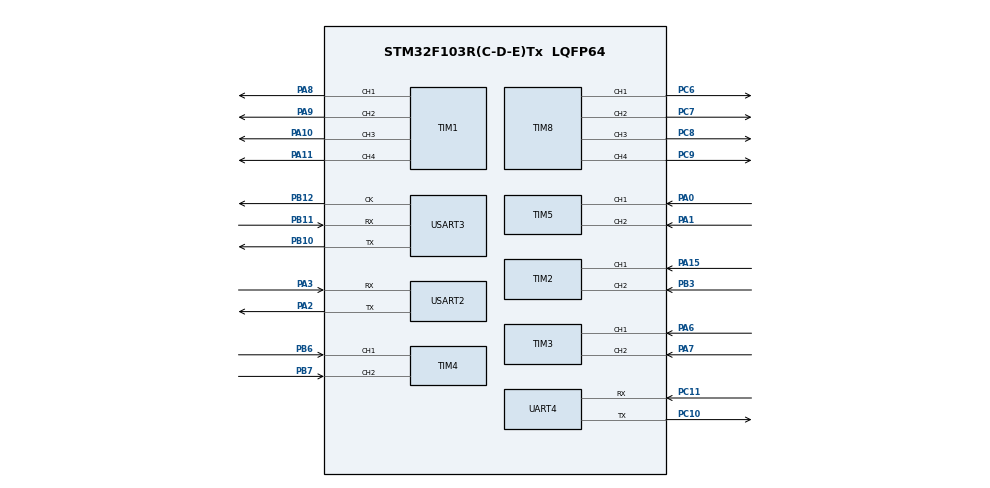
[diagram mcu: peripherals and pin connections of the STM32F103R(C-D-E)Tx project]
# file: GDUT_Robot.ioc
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Dma.Request0=USART3_RX
Dma.Request1=USART3_TX
Dma.USART3_RX.0.Direction=DMA_PERIPH_TO_MEMORY
Dma.USART3_RX.0.Instance=DMA1_Channel3
Dma.USART3_RX.0.MemDataAlignment=DMA_MDATAALIGN_BYTE
Dma.USART3_RX.0.MemInc=DMA_MINC_ENABLE
Dma.USART3_RX.0.Mode=DMA_NORMAL
Dma.USART3_RX.0.PeriphDataAlignment=DMA_PDATAALIGN_BYTE
Dma.USART3_RX.0.PeriphInc=DMA_PINC_DISABLE
Dma.USART3_RX.0.Priority=DMA_PRIORITY_MEDIUM
Dma.USART3_TX.1.Direction=DMA_MEMORY_TO_PERIPH
Dma.USART3_TX.1.Instance=DMA1_Channel2
Dma.USART3_TX.1.MemDataAlignment=DMA_MDATAALIGN_BYTE
Dma.USART3_TX.1.MemInc=DMA_MINC_ENABLE
Dma.USART3_TX.1.Mode=DMA_NORMAL
Dma.USART3_TX.1.PeriphDataAlignment=DMA_PDATAALIGN_BYTE
Dma.USART3_TX.1.PeriphInc=DMA_PINC_DISABLE
Dma.USART3_TX.1.Priority=DMA_PRIORITY_MEDIUM
Mcu.Family=STM32F1
Mcu.Name=STM32F103R(C-D-E)Tx
Mcu.Package=LQFP64
NVIC.DMA1_Channel2_IRQn=true\:0\:0\:false\:false\:true\:false\:true
NVIC.DMA1_Channel3_IRQn=true\:0\:0\:false\:false\:true\:false\:true
NVIC.PriorityGroup=NVIC_PRIORITYGROUP_4
NVIC.TIM6_IRQn=true\:0\:0\:false\:false\:true\:true\:true
NVIC.UART4_IRQn=true\:0\:0\:false\:false\:true\:true\:true
NVIC.USART3_IRQn=true\:0\:0\:false\:false\:true\:true\:true
PA0-WKUP.Signal=S_TIM5_CH1
PA1.Signal=S_TIM5_CH2
PA10.Signal=S_TIM1_CH3
PA11.Signal=S_TIM1_CH4
PA13.Mode=Serial_Wire
PA13.Signal=SYS_JTMS-SWDIO
PA14.Mode=Serial_Wire
PA14.Signal=SYS_JTCK-SWCLK
PA15.Signal=S_TIM2_CH1_ETR
PA2.Mode=Asynchronous
PA2.Signal=USART2_TX
PA3.Mode=Asynchronous
PA3.Signal=USART2_RX
PA6.Signal=S_TIM3_CH1
PA7.Signal=S_TIM3_CH2
PA8.Signal=S_TIM1_CH1
PA9.Signal=S_TIM1_CH2
PB10.Mode=Synchronous
PB10.Signal=USART3_TX
PB11.Mode=Synchronous
PB11.Signal=USART3_RX
PB12.Mode=Synchronous
PB12.Signal=USART3_CK
PB3.Signal=S_TIM2_CH2
PB6.Signal=S_TIM4_CH1
PB7.Signal=S_TIM4_CH2
PC10.Mode=Asynchronous
PC10.Signal=UART4_TX
PC11.Mode=Asynchronous
PC11.Signal=UART4_RX
PC6.Signal=S_TIM8_CH1
PC7.Signal=S_TIM8_CH2
PC8.Signal=S_TIM8_CH3
PC9.Signal=S_TIM8_CH4
PD0-OSC_IN.Mode=HSE-External-Oscillator
PD0-OSC_IN.Signal=RCC_OSC_IN
PD1-OSC_OUT.Mode=HSE-External-Oscillator
PD1-OSC_OUT.Signal=RCC_OSC_OUT
ProjectManager.HeapSize=0x200
ProjectManager.StackSize=0x400
ProjectManager.TargetToolchain=SW4STM32
RCC.APB1Freq_Value=8000000
RCC.APB2Freq_Value=8000000
SH.S_TIM1_CH1.0=TIM1_CH1,PWM Generation1 CH1
SH.S_TIM1_CH2.0=TIM1_CH2,PWM Generation2 CH2
SH.S_TIM1_CH3.0=TIM1_CH3,Output Compare3 CH3
SH.S_TIM1_CH4.0=TIM1_CH4,Output Compare4 CH4
SH.S_TIM2_CH1_ETR.0=TIM2_CH1,Encoder_Interface
SH.S_TIM2_CH2.0=TIM2_CH2,Encoder_Interface
SH.S_TIM3_CH1.0=TIM3_CH1,Encoder_Interface
SH.S_TIM3_CH2.0=TIM3_CH2,Encoder_Interface
SH.S_TIM4_CH1.0=TIM4_CH1,Encoder_Interface
SH.S_TIM4_CH2.0=TIM4_CH2,Encoder_Interface
SH.S_TIM5_CH1.0=TIM5_CH1,Encoder_Interface
SH.S_TIM5_CH2.0=TIM5_CH2,Encoder_Interface
SH.S_TIM8_CH1.0=TIM8_CH1,Output Compare1 CH1
SH.S_TIM8_CH2.0=TIM8_CH2,Output Compare2 CH2
SH.S_TIM8_CH3.0=TIM8_CH3,Output Compare3 CH3
SH.S_TIM8_CH4.0=TIM8_CH4,Output Compare4 CH4
TIM1.Channel-Output\ Compare3\ CH3=TIM_CHANNEL_3
TIM1.Channel-Output\ Compare4\ CH4=TIM_CHANNEL_4
TIM1.Channel-PWM\ Generation1\ CH1=TIM_CHANNEL_1
TIM1.Channel-PWM\ Generation2\ CH2=TIM_CHANNEL_2
TIM6.Period=7200-1
TIM6.Prescaler=10-1
TIM8.Channel-Output\ Compare1\ CH1=TIM_CHANNEL_1
TIM8.Channel-Output\ Compare2\ CH2=TIM_CHANNEL_2
TIM8.Channel-Output\ Compare3\ CH3=TIM_CHANNEL_3
TIM8.Channel-Output\ Compare4\ CH4=TIM_CHANNEL_4
UART4.VirtualMode=Asynchronous
USART2.VirtualMode=VM_ASYNC
USART3.VirtualMode=VM_SYNC
VP_TIM1_VS_ClockSourceINT.Mode=Internal
VP_TIM6_VS_ClockSourceINT.Mode=Enable_Timer
VP_TIM8_VS_ClockSourceINT.Mode=Internal
board=custom

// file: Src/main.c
/* USER CODE BEGIN Header */
/**
 ******************************************************************************
 * @file           : main.c
 * @brief          : Main program body
 ******************************************************************************
 * @attention
 *
 * <h2><center>&copy; Copyright (c) 2021 STMicroelectronics.
 * All rights reserved.</center></h2>
 *
 * This software component is licensed by ST under BSD 3-Clause license,
 * the "License"; You may not use this file except in compliance with the
 * License. You may obtain a copy of the License at:
 *                        opensource.org/licenses/BSD-3-Clause
 *
 ******************************************************************************
 */
/* USER CODE END Header */
#include "main.h"

/* USER CODE BEGIN Includes */
#include "PID_struct.h"
#include "motor.h"
#include "tim_it.h"
#include "retarget.h"
/* USER CODE END Includes */

TIM_HandleTypeDef htim1;
TIM_HandleTypeDef htim2;
TIM_HandleTypeDef htim3;
TIM_HandleTypeDef htim4;
TIM_HandleTypeDef htim5;
TIM_HandleTypeDef htim6;
TIM_HandleTypeDef htim8;

UART_HandleTypeDef huart4;
UART_HandleTypeDef huart2;
USART_HandleTypeDef husart3;
DMA_HandleTypeDef hdma_usart3_rx;
DMA_HandleTypeDef hdma_usart3_tx;

void SystemClock_Config(void);
static void MX_GPIO_Init(void);
static void MX_DMA_Init(void);
static void MX_TIM1_Init(void);
static void MX_TIM3_Init(void);
static void MX_TIM6_Init(void);
static void MX_UART4_Init(void);
static void MX_USART3_Init(void);
static void MX_TIM2_Init(void);
static void MX_USART2_UART_Init(void);
static void MX_TIM5_Init(void);
static void MX_TIM8_Init(void);
static void MX_TIM4_Init(void);

int main(void)
{

  /* MCU Configuration--------------------------------------------------------*/

  /* Reset of all peripherals, Initializes the Flash interface and the Systick. */
  HAL_Init();

  /* Configure the system clock */
  SystemClock_Config();

  /* Initialize all configured peripherals */
  MX_GPIO_Init();
  MX_DMA_Init();
  MX_TIM1_Init();
  MX_TIM3_Init();
  MX_TIM6_Init();
  MX_UART4_Init();
  MX_USART3_Init();
  MX_TIM2_Init();
  MX_USART2_UART_Init();
  MX_TIM5_Init();
  MX_TIM8_Init();
  MX_TIM4_Init();
  /* USER CODE BEGIN 2 */
    RetargetInit(&huart2);
    step = 0;
    PID_Init(); //
    HAL_TIM_Base_Start_IT(&htim6);
    printf("ball ball you  1\n");
  /* USER CODE END 2 */

  /* Infinite loop */
    while (1){

    }
}

void SystemClock_Config(void)
{
  RCC_OscInitTypeDef RCC_OscInitStruct = {0};
  RCC_ClkInitTypeDef RCC_ClkInitStruct = {0};

  /** Initializes the RCC Oscillators according to the specified parameters
  * in the RCC_OscInitTypeDef structure.
  */
  RCC_OscInitStruct.OscillatorType = RCC_OSCILLATORTYPE_HSI;
  RCC_OscInitStruct.HSIState = RCC_HSI_ON;
  RCC_OscInitStruct.HSICalibrationValue = RCC_HSICALIBRATION_DEFAULT;
  RCC_OscInitStruct.PLL.PLLState = RCC_PLL_NONE;
  if (HAL_RCC_OscConfig(&RCC_OscInitStruct) != HAL_OK)
  {
    Error_Handler();
  }
  /** Initializes the CPU, AHB and APB buses clocks
  */
  RCC_ClkInitStruct.ClockType = RCC_CLOCKTYPE_HCLK|RCC_CLOCKTYPE_SYSCLK
                              |RCC_CLOCKTYPE_PCLK1|RCC_CLOCKTYPE_PCLK2;
  RCC_ClkInitStruct.SYSCLKSource = RCC_SYSCLKSOURCE_HSI;
  RCC_ClkInitStruct.AHBCLKDivider = RCC_SYSCLK_DIV1;
  RCC_ClkInitStruct.APB1CLKDivider = RCC_HCLK_DIV1;
  RCC_ClkInitStruct.APB2CLKDivider = RCC_HCLK_DIV1;

  if (HAL_RCC_ClockConfig(&RCC_ClkInitStruct, FLASH_LATENCY_0) != HAL_OK)
  {
    Error_Handler();
  }
}

static void MX_TIM1_Init(void)
{

  TIM_ClockConfigTypeDef sClockSourceConfig = {0};
  TIM_MasterConfigTypeDef sMasterConfig = {0};
  TIM_OC_InitTypeDef sConfigOC = {0};
  TIM_BreakDeadTimeConfigTypeDef sBreakDeadTimeConfig = {0};

  htim1.Instance = TIM1;
  htim1.Init.Prescaler = 0;
  htim1.Init.CounterMode = TIM_COUNTERMODE_UP;
  htim1.Init.Period = 65535;
  htim1.Init.ClockDivision = TIM_CLOCKDIVISION_DIV1;
  htim1.Init.RepetitionCounter = 0;
  htim1.Init.AutoReloadPreload = TIM_AUTORELOAD_PRELOAD_DISABLE;
  if (HAL_TIM_Base_Init(&htim1) != HAL_OK)
  {
    Error_Handler();
  }
  sClockSourceConfig.ClockSource = TIM_CLOCKSOURCE_INTERNAL;
  if (HAL_TIM_ConfigClockSource(&htim1, &sClockSourceConfig) != HAL_OK)
  {
    Error_Handler();
  }
  if (HAL_TIM_PWM_Init(&htim1) != HAL_OK)
  {
    Error_Handler();
  }
  if (HAL_TIM_OC_Init(&htim1) != HAL_OK)
  {
    Error_Handler();
  }
  sMasterConfig.MasterOutputTrigger = TIM_TRGO_RESET;
  sMasterConfig.MasterSlaveMode = TIM_MASTERSLAVEMODE_DISABLE;
  if (HAL_TIMEx_MasterConfigSynchronization(&htim1, &sMasterConfig) != HAL_OK)
  {
    Error_Handler();
  }
  sConfigOC.OCMode = TIM_OCMODE_PWM1;
  sConfigOC.Pulse = 0;
  sConfigOC.OCPolarity = TIM_OCPOLARITY_HIGH;
  sConfigOC.OCNPolarity = TIM_OCNPOLARITY_HIGH;
  sConfigOC.OCFastMode = TIM_OCFAST_DISABLE;
  sConfigOC.OCIdleState = TIM_OCIDLESTATE_RESET;
  sConfigOC.OCNIdleState = TIM_OCNIDLESTATE_RESET;
  if (HAL_TIM_PWM_ConfigChannel(&htim1, &sConfigOC, TIM_CHANNEL_1) != HAL_OK)
  {
    Error_Handler();
  }
  if (HAL_TIM_PWM_ConfigChannel(&htim1, &sConfigOC, TIM_CHANNEL_2) != HAL_OK)
  {
    Error_Handler();
  }
  sConfigOC.OCMode = TIM_OCMODE_TIMING;
  if (HAL_TIM_OC_ConfigChannel(&htim1, &sConfigOC, TIM_CHANNEL_3) != HAL_OK)
  {
    Error_Handler();
  }
  if (HAL_TIM_OC_ConfigChannel(&htim1, &sConfigOC, TIM_CHANNEL_4) != HAL_OK)
  {
    Error_Handler();
  }
  sBreakDeadTimeConfig.OffStateRunMode = TIM_OSSR_DISABLE;
  sBreakDeadTimeConfig.OffStateIDLEMode = TIM_OSSI_DISABLE;
  sBreakDeadTimeConfig.LockLevel = TIM_LOCKLEVEL_OFF;
  sBreakDeadTimeConfig.DeadTime = 0;
  sBreakDeadTimeConfig.BreakState = TIM_BREAK_DISABLE;
  sBreakDeadTimeConfig.BreakPolarity = TIM_BREAKPOLARITY_HIGH;
  sBreakDeadTimeConfig.AutomaticOutput = TIM_AUTOMATICOUTPUT_DISABLE;
  if (HAL_TIMEx_ConfigBreakDeadTime(&htim1, &sBreakDeadTimeConfig) != HAL_OK)
  {
    Error_Handler();
  }
  HAL_TIM_MspPostInit(&htim1);

}

static void MX_TIM2_Init(void)
{

  TIM_Encoder_InitTypeDef sConfig = {0};
  TIM_MasterConfigTypeDef sMasterConfig = {0};

  htim2.Instance = TIM2;
  htim2.Init.Prescaler = 0;
  htim2.Init.CounterMode = TIM_COUNTERMODE_UP;
  htim2.Init.Period = 65535;
  htim2.Init.ClockDivision = TIM_CLOCKDIVISION_DIV1;
  htim2.Init.AutoReloadPreload = TIM_AUTORELOAD_PRELOAD_DISABLE;
  sConfig.EncoderMode = TIM_ENCODERMODE_TI1;
  sConfig.IC1Polarity = TIM_ICPOLARITY_RISING;
  sConfig.IC1Selection = TIM_ICSELECTION_DIRECTTI;
  sConfig.IC1Prescaler = TIM_ICPSC_DIV1;
  sConfig.IC1Filter = 0;
  sConfig.IC2Polarity = TIM_ICPOLARITY_RISING;
  sConfig.IC2Selection = TIM_ICSELECTION_DIRECTTI;
  sConfig.IC2Prescaler = TIM_ICPSC_DIV1;
  sConfig.IC2Filter = 0;
  if (HAL_TIM_Encoder_Init(&htim2, &sConfig) != HAL_OK)
  {
    Error_Handler();
  }
  sMasterConfig.MasterOutputTrigger = TIM_TRGO_RESET;
  sMasterConfig.MasterSlaveMode = TIM_MASTERSLAVEMODE_DISABLE;
  if (HAL_TIMEx_MasterConfigSynchronization(&htim2, &sMasterConfig) != HAL_OK)
  {
    Error_Handler();
  }

}

static void MX_TIM3_Init(void)
{

  TIM_Encoder_InitTypeDef sConfig = {0};
  TIM_MasterConfigTypeDef sMasterConfig = {0};

  htim3.Instance = TIM3;
  htim3.Init.Prescaler = 0;
  htim3.Init.CounterMode = TIM_COUNTERMODE_UP;
  htim3.Init.Period = 65535;
  htim3.Init.ClockDivision = TIM_CLOCKDIVISION_DIV1;
  htim3.Init.AutoReloadPreload = TIM_AUTORELOAD_PRELOAD_DISABLE;
  sConfig.EncoderMode = TIM_ENCODERMODE_TI1;
  sConfig.IC1Polarity = TIM_ICPOLARITY_RISING;
  sConfig.IC1Selection = TIM_ICSELECTION_DIRECTTI;
  sConfig.IC1Prescaler = TIM_ICPSC_DIV1;
  sConfig.IC1Filter = 0;
  sConfig.IC2Polarity = TIM_ICPOLARITY_RISING;
  sConfig.IC2Selection = TIM_ICSELECTION_DIRECTTI;
  sConfig.IC2Prescaler = TIM_ICPSC_DIV1;
  sConfig.IC2Filter = 0;
  if (HAL_TIM_Encoder_Init(&htim3, &sConfig) != HAL_OK)
  {
    Error_Handler();
  }
  sMasterConfig.MasterOutputTrigger = TIM_TRGO_RESET;
  sMasterConfig.MasterSlaveMode = TIM_MASTERSLAVEMODE_DISABLE;
  if (HAL_TIMEx_MasterConfigSynchronization(&htim3, &sMasterConfig) != HAL_OK)
  {
    Error_Handler();
  }

}

static void MX_TIM4_Init(void)
{

  TIM_Encoder_InitTypeDef sConfig = {0};
  TIM_MasterConfigTypeDef sMasterConfig = {0};

  htim4.Instance = TIM4;
  htim4.Init.Prescaler = 0;
  htim4.Init.CounterMode = TIM_COUNTERMODE_UP;
  htim4.Init.Period = 65535;
  htim4.Init.ClockDivision = TIM_CLOCKDIVISION_DIV1;
  htim4.Init.AutoReloadPreload = TIM_AUTORELOAD_PRELOAD_DISABLE;
  sConfig.EncoderMode = TIM_ENCODERMODE_TI1;
  sConfig.IC1Polarity = TIM_ICPOLARITY_RISING;
  sConfig.IC1Selection = TIM_ICSELECTION_DIRECTTI;
  sConfig.IC1Prescaler = TIM_ICPSC_DIV1;
  sConfig.IC1Filter = 0;
  sConfig.IC2Polarity = TIM_ICPOLARITY_RISING;
  sConfig.IC2Selection = TIM_ICSELECTION_DIRECTTI;
  sConfig.IC2Prescaler = TIM_ICPSC_DIV1;
  sConfig.IC2Filter = 0;
  if (HAL_TIM_Encoder_Init(&htim4, &sConfig) != HAL_OK)
  {
    Error_Handler();
  }
  sMasterConfig.MasterOutputTrigger = TIM_TRGO_RESET;
  sMasterConfig.MasterSlaveMode = TIM_MASTERSLAVEMODE_DISABLE;
  if (HAL_TIMEx_MasterConfigSynchronization(&htim4, &sMasterConfig) != HAL_OK)
  {
    Error_Handler();
  }

}

static void MX_TIM5_Init(void)
{

  TIM_Encoder_InitTypeDef sConfig = {0};
  TIM_MasterConfigTypeDef sMasterConfig = {0};

  htim5.Instance = TIM5;
  htim5.Init.Prescaler = 0;
  htim5.Init.CounterMode = TIM_COUNTERMODE_UP;
  htim5.Init.Period = 65535;
  htim5.Init.ClockDivision = TIM_CLOCKDIVISION_DIV1;
  htim5.Init.AutoReloadPreload = TIM_AUTORELOAD_PRELOAD_DISABLE;
  sConfig.EncoderMode = TIM_ENCODERMODE_TI1;
  sConfig.IC1Polarity = TIM_ICPOLARITY_RISING;
  sConfig.IC1Selection = TIM_ICSELECTION_DIRECTTI;
  sConfig.IC1Prescaler = TIM_ICPSC_DIV1;
  sConfig.IC1Filter = 0;
  sConfig.IC2Polarity = TIM_ICPOLARITY_RISING;
  sConfig.IC2Selection = TIM_ICSELECTION_DIRECTTI;
  sConfig.IC2Prescaler = TIM_ICPSC_DIV1;
  sConfig.IC2Filter = 0;
  if (HAL_TIM_Encoder_Init(&htim5, &sConfig) != HAL_OK)
  {
    Error_Handler();
  }
  sMasterConfig.MasterOutputTrigger = TIM_TRGO_RESET;
  sMasterConfig.MasterSlaveMode = TIM_MASTERSLAVEMODE_DISABLE;
  if (HAL_TIMEx_MasterConfigSynchronization(&htim5, &sMasterConfig) != HAL_OK)
  {
    Error_Handler();
  }

}

static void MX_TIM6_Init(void)
{

  TIM_MasterConfigTypeDef sMasterConfig = {0};

  htim6.Instance = TIM6;
  htim6.Init.Prescaler = 10-1;
  htim6.Init.CounterMode = TIM_COUNTERMODE_UP;
  htim6.Init.Period = 7200-1;
  htim6.Init.AutoReloadPreload = TIM_AUTORELOAD_PRELOAD_DISABLE;
  if (HAL_TIM_Base_Init(&htim6) != HAL_OK)
  {
    Error_Handler();
  }
  sMasterConfig.MasterOutputTrigger = TIM_TRGO_RESET;
  sMasterConfig.MasterSlaveMode = TIM_MASTERSLAVEMODE_DISABLE;
  if (HAL_TIMEx_MasterConfigSynchronization(&htim6, &sMasterConfig) != HAL_OK)
  {
    Error_Handler();
  }

}

static void MX_TIM8_Init(void)
{

  TIM_ClockConfigTypeDef sClockSourceConfig = {0};
  TIM_MasterConfigTypeDef sMasterConfig = {0};
  TIM_OC_InitTypeDef sConfigOC = {0};
  TIM_BreakDeadTimeConfigTypeDef sBreakDeadTimeConfig = {0};

  htim8.Instance = TIM8;
  htim8.Init.Prescaler = 0;
  htim8.Init.CounterMode = TIM_COUNTERMODE_UP;
  htim8.Init.Period = 65535;
  htim8.Init.ClockDivision = TIM_CLOCKDIVISION_DIV1;
  htim8.Init.RepetitionCounter = 0;
  htim8.Init.AutoReloadPreload = TIM_AUTORELOAD_PRELOAD_DISABLE;
  if (HAL_TIM_Base_Init(&htim8) != HAL_OK)
  {
    Error_Handler();
  }
  sClockSourceConfig.ClockSource = TIM_CLOCKSOURCE_INTERNAL;
  if (HAL_TIM_ConfigClockSource(&htim8, &sClockSourceConfig) != HAL_OK)
  {
    Error_Handler();
  }
  if (HAL_TIM_OC_Init(&htim8) != HAL_OK)
  {
    Error_Handler();
  }
  sMasterConfig.MasterOutputTrigger = TIM_TRGO_RESET;
  sMasterConfig.MasterSlaveMode = TIM_MASTERSLAVEMODE_DISABLE;
  if (HAL_TIMEx_MasterConfigSynchronization(&htim8, &sMasterConfig) != HAL_OK)
  {
    Error_Handler();
  }
  sConfigOC.OCMode = TIM_OCMODE_TIMING;
  sConfigOC.Pulse = 0;
  sConfigOC.OCPolarity = TIM_OCPOLARITY_HIGH;
  sConfigOC.OCNPolarity = TIM_OCNPOLARITY_HIGH;
  sConfigOC.OCFastMode = TIM_OCFAST_DISABLE;
  sConfigOC.OCIdleState = TIM_OCIDLESTATE_RESET;
  sConfigOC.OCNIdleState = TIM_OCNIDLESTATE_RESET;
  if (HAL_TIM_OC_ConfigChannel(&htim8, &sConfigOC, TIM_CHANNEL_1) != HAL_OK)
  {
    Error_Handler();
  }
  if (HAL_TIM_OC_ConfigChannel(&htim8, &sConfigOC, TIM_CHANNEL_2) != HAL_OK)
  {
    Error_Handler();
  }
  if (HAL_TIM_OC_ConfigChannel(&htim8, &sConfigOC, TIM_CHANNEL_3) != HAL_OK)
  {
    Error_Handler();
  }
  if (HAL_TIM_OC_ConfigChannel(&htim8, &sConfigOC, TIM_CHANNEL_4) != HAL_OK)
  {
    Error_Handler();
  }
  sBreakDeadTimeConfig.OffStateRunMode = TIM_OSSR_DISABLE;
  sBreakDeadTimeConfig.OffStateIDLEMode = TIM_OSSI_DISABLE;
  sBreakDeadTimeConfig.LockLevel = TIM_LOCKLEVEL_OFF;
  sBreakDeadTimeConfig.DeadTime = 0;
  sBreakDeadTimeConfig.BreakState = TIM_BREAK_DISABLE;
  sBreakDeadTimeConfig.BreakPolarity = TIM_BREAKPOLARITY_HIGH;
  sBreakDeadTimeConfig.AutomaticOutput = TIM_AUTOMATICOUTPUT_DISABLE;
  if (HAL_TIMEx_ConfigBreakDeadTime(&htim8, &sBreakDeadTimeConfig) != HAL_OK)
  {
    Error_Handler();
  }
  HAL_TIM_MspPostInit(&htim8);

}

static void MX_UART4_Init(void)
{

  huart4.Instance = UART4;
  huart4.Init.BaudRate = 115200;
  huart4.Init.WordLength = UART_WORDLENGTH_8B;
  huart4.Init.StopBits = UART_STOPBITS_1;
  huart4.Init.Parity = UART_PARITY_NONE;
  huart4.Init.Mode = UART_MODE_TX_RX;
  huart4.Init.HwFlowCtl = UART_HWCONTROL_NONE;
  huart4.Init.OverSampling = UART_OVERSAMPLING_16;
  if (HAL_UART_Init(&huart4) != HAL_OK)
  {
    Error_Handler();
  }

}

static void MX_USART2_UART_Init(void)
{

  huart2.Instance = USART2;
  huart2.Init.BaudRate = 115200;
  huart2.Init.WordLength = UART_WORDLENGTH_8B;
  huart2.Init.StopBits = UART_STOPBITS_1;
  huart2.Init.Parity = UART_PARITY_NONE;
  huart2.Init.Mode = UART_MODE_TX_RX;
  huart2.Init.HwFlowCtl = UART_HWCONTROL_NONE;
  huart2.Init.OverSampling = UART_OVERSAMPLING_16;
  if (HAL_UART_Init(&huart2) != HAL_OK)
  {
    Error_Handler();
  }

}

static void MX_USART3_Init(void)
{

  husart3.Instance = USART3;
  husart3.Init.BaudRate = 115200;
  husart3.Init.WordLength = USART_WORDLENGTH_8B;
  husart3.Init.StopBits = USART_STOPBITS_1;
  husart3.Init.Parity = USART_PARITY_NONE;
  husart3.Init.Mode = USART_MODE_TX_RX;
  husart3.Init.CLKPolarity = USART_POLARITY_LOW;
  husart3.Init.CLKPhase = USART_PHASE_1EDGE;
  husart3.Init.CLKLastBit = USART_LASTBIT_DISABLE;
  if (HAL_USART_Init(&husart3) != HAL_OK)
  {
    Error_Handler();
  }

}

static void MX_DMA_Init(void)
{

  /* DMA controller clock enable */
  __HAL_RCC_DMA1_CLK_ENABLE();

  /* DMA interrupt init */
  /* DMA1_Channel2_IRQn interrupt configuration */
  HAL_NVIC_SetPriority(DMA1_Channel2_IRQn, 0, 0);
  HAL_NVIC_EnableIRQ(DMA1_Channel2_IRQn);
  /* DMA1_Channel3_IRQn interrupt configuration */
  HAL_NVIC_SetPriority(DMA1_Channel3_IRQn, 0, 0);
  HAL_NVIC_EnableIRQ(DMA1_Channel3_IRQn);

}

static void MX_GPIO_Init(void)
{

  /* GPIO Ports Clock Enable */
  __HAL_RCC_GPIOD_CLK_ENABLE();
  __HAL_RCC_GPIOA_CLK_ENABLE();
  __HAL_RCC_GPIOB_CLK_ENABLE();
  __HAL_RCC_GPIOC_CLK_ENABLE();

}

void Error_Handler(void)
{
}

#ifdef  USE_FULL_ASSERT
/**
  * @brief  Reports the name of the source file and the source line number
  *         where the assert_param error has occurred.
  * @param  file: pointer to the source file name
  * @param  line: assert_param error line source number
  * @retval None
  */
void assert_failed(uint8_t *file, uint32_t line)
{
  /* USER CODE BEGIN 6 */
  /* User can add his own implementation to report the file name and line
     number,
     tex: printf("Wrong parameters value: file %s on line %d\r\n", file, line)
   */
  /* USER CODE END 6 */
}
#endif /* USE_FULL_ASSERT */

/************************ (C) COPYRIGHT STMicroelectronics *****END OF FILE****/
